# R40 register map
Vendor: Allwinner; Series: R40; File version: 0.1
CPU: CA7 0, little endian, MPU, FPU, double-precision FPU, 0 interrupt priority bits
Registers are 32-bit, read-write, reset 0x0 unless marked. A register's access mark holds for its fields unless they carry their own. Offsets are from the block's base; [hi:lo] are bit positions.

## CE_NS
Base 0x01C15000
Same registers: CE_S 0x01C15800
0x00 CE_TDA — Task Descriptor Address
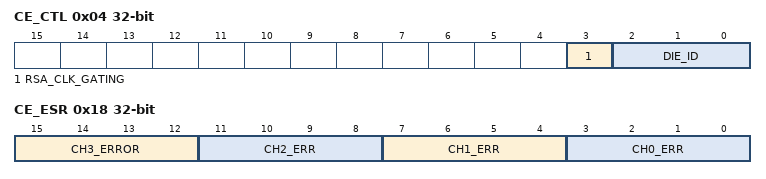
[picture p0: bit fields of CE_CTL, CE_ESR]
0x04 CE_CTL (reset mask 0x8) — Control Register
  [3] RSA_CLK_GATING — RSA CLK Gating Enable(only for S world) 0: RSA clk gating enable 1: RSA clk gating disable
    0=enable (RSA clk gating enable); 1=disable (RSA clk gating disable)
  [2:0] DIE_ID ro — Die Bonding ID
0x08 CE_ICR — Interrupt Control Register
  [3:0] TASK_INT_EN — Task channel0-3 interrupt enable 0: interrupt disable 1: interrupt enable
0x0C CE_ISR — Interrupt Status Register
  [3:0] TASK_END_PENDING — Task channel0-3 end pending 0: Not finished 1: Finished It indicates if task has been completed . Notes: Write `1` to clear it.
0x10 CE_TLR — Task Load Register
  [0] TASK_LOAD — Task Load When set, CE can load the descriptor of task if task FIFO is not full.
0x14 CE_TSR — Task Status Register
  [1:0] TASK_CHANNEL ro — Indicate which channel is running 00: Task channel0 01: Task channel1 10: Task channel2 11: Task channel3
0x18 CE_ESR — Error Status Register
  [all] fields
    1=Algorithm not support; 2=Data length error; 4=Keysram access error for AES. Write `1` to clear it.
  [15:12] CH3_ERROR ro — Task channel3 error type xxx1: Algorithm not support xx1x: Data length error x1xx: Keysram access error for AES. Write `1` to clear it. 1xxx: Reserved
  [11:8] CH2_ERR ro — Task channel2 error type xxx1: Algorithm not support xx1x: Data length error x1xx: Keysram access error for AES. Write `1` to clear it. 1xxx: Reserved
  [7:4] CH1_ERR ro — Task channel1 error type xxx1: Algorithm not support xx1x: Data length error x1xx: Keysram access error for AES. Write `1` to clear it. 1xxx: Reserved
  [3:0] CH0_ERR ro — Task channel0 error type xxx1: Algorithm not support xx1x: Data length error x1xx: Keysram access error for AES. Write `1` to clear it. 1xxx: Reserved
0x24 CE_CSA — DMA Current Source Address
  [31:0] SRC_ADR ro — Current source address
0x28 CE_CDA — DMA Current Destination Address
  [31:0] DES_ADR ro — Current destination address
0x2C CE_TPR — Throughput Register
  [31:0] THROUGHPUT — It indicates the throughput of the last time to this register. Writing 0 to this register will clear it.

## KeyPad
Base 0x01C23000
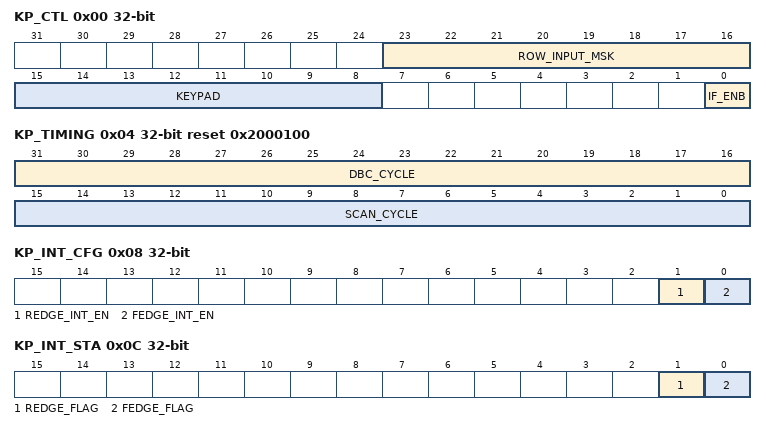
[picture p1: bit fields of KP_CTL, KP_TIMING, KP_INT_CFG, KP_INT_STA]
0x00 KP_CTL — Keypad Control Register
  [23:16] ROW_INPUT_MSK — Keypad Row Input Mask When set to `1`, the corresponding input is masked.
  [15:8] KEYPAD — Keypad Column Output Mask When set to `1`, the corresponding output is masked.
  [0] IF_ENB — Keypad Interface Enable 0: Disable 1: Enable
    0=Disable; 1=Enable
0x04 KP_TIMING reset 0x2000100 — Keypad Timing Parameter Register
  [31:16] DBC_CYCLE — Keypad Debounce Clock Cycle n It is used for filter switching noises. When row input is low level, the Keypad Interface would delay (n+1) clock to check whether it is still keeping on low level. If it is true, the Keypad Interface would scan the state of the external keypad and get the state into internal registers. After scan, the interrupt is generated if enabled. Note: The value below 0x10 can not be used.
  [15:0] SCAN_CYCLE — Keypad Scan Period Clock Cycle n When the Keypad Interface is enabled, it would scan the external keypad in period. The period time is 8*(n+1)/kp_clk. The kp_clk is input clock for Keypad Interface from CCU. Notes: The value below 0x10 can`t be used.
0x08 KP_INT_CFG — Keypad Interrupt Configure Register
  [1] REDGE_INT_EN — Keypad input rising edge (key release) interrupt enable 0: Disable 1: Enable
    0=Disable; 1=Enable
  [0] FEDGE_INT_EN — Keypad input falling edge (key press) interrupt enable 0: Disable 1: Enable
    0=Disable; 1=Enable
0x0C KP_INT_STA — Keypad Interrupt Status Register
  [1] REDGE_FLAG write-1-clears — Keypad input rising edge (key release) interrupt status When it is `1`, the key released interrupt occurred. The interrupt is cleared by writing `1`.
  [0] FEDGE_FLAG write-1-clears — Keypad input falling edge (key press) interrupt status When it is `1`, the corresponding pressed interrupt occurred. The interrupt is cleared by writing `1`.
0x10 KP_IN0 reset not defined — Keypad Row Input Data Register 0
0x14 KP_IN1 reset not defined — Keypad Row Input Data Register 1
